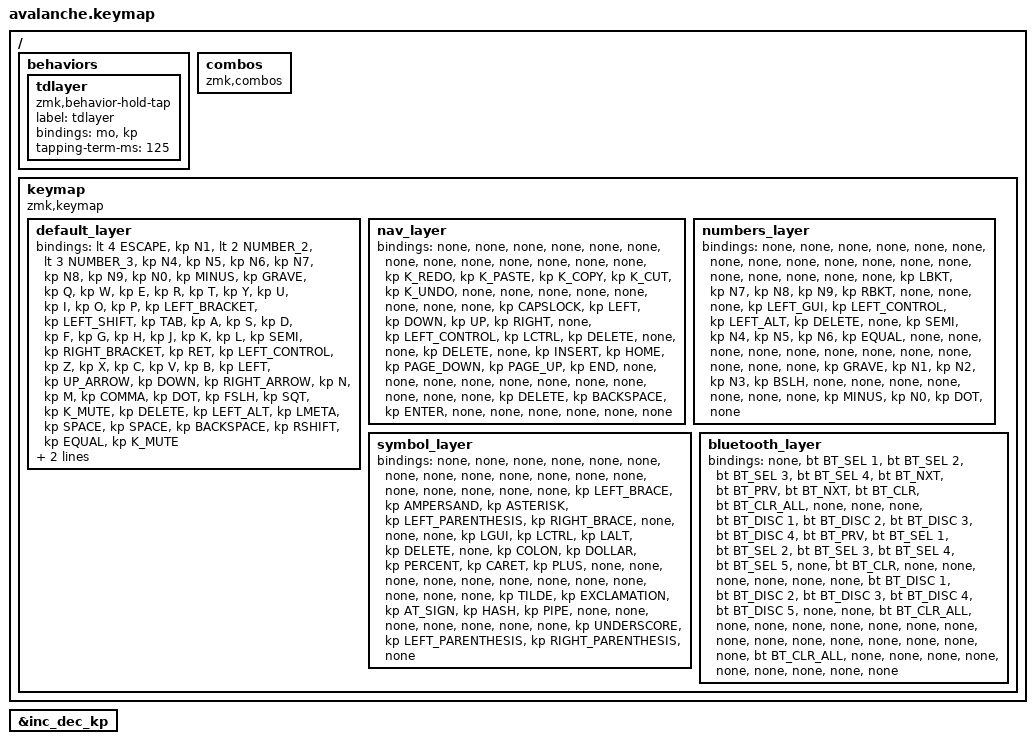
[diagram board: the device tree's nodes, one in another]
#include <behaviors.dtsi>
#include <dt-bindings/zmk/bt.h>
#include <dt-bindings/zmk/keys.h>

&inc_dec_kp {
};

/ {
    behaviors {
        tdlayer: tdlayer {
            compatible = "zmk,behavior-hold-tap";
            #binding-cells = <2>;
            label = "tdlayer";
            bindings = <&mo>, <&kp>;

            tapping-term-ms = <125>;
        };
    };

    combos { compatible = "zmk,combos"; };

    keymap {
        compatible = "zmk,keymap";

        /*
        &none  &none  &none  &none  &none  &none                                   &none  &none  &none  &none  &none  &none 
// ------------------------------------------------------------------------------------------------------------------------------------------------------------------------------------
        &none  &none  &none  &none  &none  &none                                   &none  &none  &none  &none  &none  &none 
// ------------------------------------------------------------------------------------------------------------------------------------------------------------------------------------
&none  &none  &none  &none  &none  &none  &none                                   &none  &none  &none  &none  &none  &none  &none 
// ------------------------------------------------------------------------------------------------------------------------------------------------------------------------------------
        &none  &none  &none  &none  &none  &none  &none  &none    &none &none  &none  &none  &none  &none  &none  &none 
// ------------------------------------------------------------------------------------------------------------------------------------------------------------------------------------
                                &none  &none  &none  &none  &none    &none &none  &none  &none  &none
*/

        default_layer {
            bindings = <
&lt 4 ESCAPE  &kp N1  &lt 2 NUMBER_2  &lt 3 NUMBER_3  &kp N4  &kp N5  &kp N6  &kp N7  &kp N8  &kp N9  &kp N0  &kp MINUS  &kp GRAVE  &kp Q  &kp W  &kp E  &kp R  &kp T  &kp Y  &kp U  &kp I  &kp O  &kp P  &kp LEFT_BRACKET  &kp LEFT_SHIFT  &kp TAB  &kp A  &kp S  &kp D  &kp F  &kp G  &kp H  &kp J  &kp K  &kp L  &kp SEMI  &kp RIGHT_BRACKET  &kp RET  &kp LEFT_CONTROL  &kp Z  &kp X  &kp C  &kp V  &kp B  &kp LEFT  &kp UP_ARROW  &kp DOWN  &kp RIGHT_ARROW  &kp N  &kp M  &kp COMMA  &kp DOT  &kp FSLH  &kp SQT  &kp K_MUTE  &kp DELETE  &kp LEFT_ALT  &kp LMETA  &kp SPACE  &kp SPACE  &kp BACKSPACE  &kp RSHIFT  &kp EQUAL  &kp K_MUTE
            >;

            sensor-bindings = <&inc_dec_kp C_VOL_UP C_VOL_DN &inc_dec_kp C_VOL_UP C_VOL_DN>;
        };

        nav_layer {
            bindings = <
&none  &none  &none  &none  &none  &none  &none  &none  &none  &none  &none  &none  &none  &kp K_REDO  &kp K_PASTE  &kp K_COPY  &kp K_CUT  &kp K_UNDO  &none  &none  &none  &none  &none  &none  &none  &none  &kp CAPSLOCK  &kp LEFT  &kp DOWN  &kp UP  &kp RIGHT  &none  &kp LEFT_CONTROL  &kp LCTRL  &kp DELETE  &none  &none  &kp DELETE  &none  &kp INSERT  &kp HOME  &kp PAGE_DOWN  &kp PAGE_UP  &kp END  &none  &none  &none  &none  &none  &none  &none  &none  &none  &none  &none  &kp DELETE  &kp BACKSPACE  &kp ENTER  &none  &none  &none  &none  &none  &none
            >;
        };

        numbers_layer {
            bindings = <
&none  &none  &none  &none  &none  &none  &none  &none  &none  &none  &none  &none  &none  &none  &none  &none  &none  &none  &kp LBKT  &kp N7  &kp N8  &kp N9  &kp RBKT  &none  &none  &none  &kp LEFT_GUI  &kp LEFT_CONTROL  &kp LEFT_ALT  &kp DELETE  &none  &kp SEMI  &kp N4  &kp N5  &kp N6  &kp EQUAL  &none  &none  &none  &none  &none  &none  &none  &none  &none  &none  &none  &none  &kp GRAVE  &kp N1  &kp N2  &kp N3  &kp BSLH  &none  &none  &none  &none  &none  &none  &none  &kp MINUS  &kp N0  &kp DOT  &none
            >;
        };

        symbol_layer {
            bindings = <
&none  &none  &none  &none  &none  &none  &none  &none  &none  &none  &none  &none  &none  &none  &none  &none  &none  &none  &kp LEFT_BRACE  &kp AMPERSAND  &kp ASTERISK  &kp LEFT_PARENTHESIS  &kp RIGHT_BRACE  &none  &none  &none  &kp LGUI  &kp LCTRL  &kp LALT  &kp DELETE  &none  &kp COLON  &kp DOLLAR  &kp PERCENT  &kp CARET  &kp PLUS  &none  &none  &none  &none  &none  &none  &none  &none  &none  &none  &none  &none  &kp TILDE  &kp EXCLAMATION  &kp AT_SIGN  &kp HASH  &kp PIPE  &none  &none  &none  &none  &none  &none  &none  &kp UNDERSCORE  &kp LEFT_PARENTHESIS  &kp RIGHT_PARENTHESIS  &none
            >;
        };

        bluetooth_layer {
            bindings = <
&none  &bt BT_SEL 1  &bt BT_SEL 2  &bt BT_SEL 3  &bt BT_SEL 4  &bt BT_NXT  &bt BT_PRV  &bt BT_NXT  &bt BT_CLR  &bt BT_CLR_ALL  &none  &none  &none  &bt BT_DISC 1  &bt BT_DISC 2  &bt BT_DISC 3  &bt BT_DISC 4  &bt BT_PRV  &bt BT_SEL 1  &bt BT_SEL 2  &bt BT_SEL 3  &bt BT_SEL 4  &bt BT_SEL 5  &none  &bt BT_CLR  &none  &none  &none  &none  &none  &none  &bt BT_DISC 1  &bt BT_DISC 2  &bt BT_DISC 3  &bt BT_DISC 4  &bt BT_DISC 5  &none  &none  &bt BT_CLR_ALL  &none  &none  &none  &none  &none  &none  &none  &none  &none  &none  &none  &none  &none  &none  &none  &bt BT_CLR_ALL  &none  &none  &none  &none  &none  &none  &none  &none  &none
            >;
        };
    };
};
